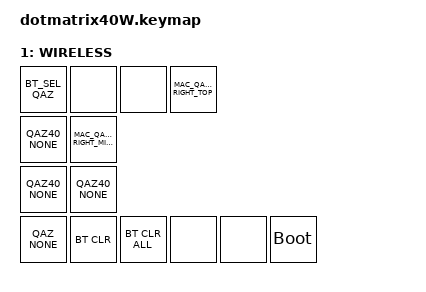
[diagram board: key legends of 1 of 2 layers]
/*
 * Copyright (c) 2021 Nick Winans
 * Copyright 2026 dotting dots
 * Copyright 2026 Tano Karbou (github: karbou12 / X: @karbou_12)
 *
 * SPDX-License-Identifier: MIT
 */

#include <behaviors.dtsi>
#include <dt-bindings/zmk/backlight.h>
#include <dt-bindings/zmk/bt.h>
#include <dt-bindings/zmk/keys.h>

#define ZMK_POINTING_DEFAULT_MOVE_VAL 1500
#define ZMK_POINTING_DEFAULT_SCRL_VAL 50

#include <dt-bindings/zmk/pointing.h>
#include <input/processors.dtsi>
#include <dt-bindings/zmk/input_transform.h>
#include <zephyr/dt-bindings/input/input-event-codes.h>
#include <zmk-input-inertia/input/processor/input_inertia.dtsi>
#include "us_keymap.h"
#include "us_encoder.h"

// ┌────┬────┬────┬────┬────┬────┬────┬────┬────┬────┬────┬────┐
// │  0 │  1 │  2 │  3 │  4 │  5 │  6 │  7 │  8 │  9 │ 10 │ 11 │
// ├────┼────┼────┼────┼────┼────┼────┼────┼────┼────┼────┼────┤
// │ 12 │ 13 │ 14 │ 15 │ 16 │ 17 │ 18 │ 19 │ 20 │ 21 │ 22 │ 23 │
// ├────┼────┼────┼────┼────┼────┼────┼────┼────┼────┼────┼────┤
// │ 24 │ 25 │ 26 │ 27 │ 28 │ 29 │ 30 │ 31 │ 32 │ 33 │ 34 │ 35 │
// ├────┼────┼────┼────┼────┴─┬──┴──┬─┴────┼────┼────┼────┼────┤
// │ 36 │ 37 │ 38 │ 39 │  40  │  E  │  41  │ 42 │ 43 │ 44 │ 45 │
// └────┴────┴────┴────┴──────┴─────┴──────┴────┴────┴────┴────┘

#define LEFT_TOP      0  1  2  3  4  5
#define RIGHT_TOP     6  7  8  9 10 11
#define LEFT_MID      12 13 14 15 16 17
#define RIGHT_MID     18 19 20 21 22 23
#define LEFT_BOTTOM   24 25 26 27 28 29
#define RIGHT_BOTTOM  30 31 32 33 34 35
#define LEFT_THUMBS   36 37 38 39 40
#define RIGHT_THUMBS  41 42 43 44 45
#define LEFT_KEYS LEFT_TOP LEFT_MID LEFT_BOTTOM
#define RIGHT_KEYS RIGHT_TOP RIGHT_MID RIGHT_BOTTOM
#define THUMBS LEFT_THUMBS RIGHT_THUMBS

// for bluetooth
#define WIRELESS  8
#define BT_SEL_QAZ  &bt BT_SEL 0  &bt BT_SEL 1  &bt BT_SEL 2  &bt BT_SEL 3

// original macro

// JIS layout fixes for Japanese OS settings
#define JP_DQUOTE       AT                // "
#define JP_AMPERSAND    CARET             // &
#define JP_QUOTE        AMPERSAND         // '
#define JP_EQUAL        UNDER             // =
#define JP_CARET        EQUAL             // ^
#define JP_YEN          0x89              // ¥
#define JP_PLUS         COLON             // +
#define JP_TILDE        PLUS              // ~
#define JP_PIPE         LS(0x89)          // |
#define JP_AT           LEFT_BRACKET      // @
#define JP_COLON        SINGLE_QUOTE      // :
#define JP_ASTERISK     DOUBLE_QUOTES     // *
#define JP_BACKQUOTE    LEFT_BRACE        // `
#define JP_UNDERSCORE   LS(0x87)          // _
#define JP_LBRACKET     RIGHT_BRACKET     // [
#define JP_RBRACKET     BACKSLASH         // ]
#define JP_LPAREN       ASTERISK          // (
#define JP_RPAREN       LEFT_PARENTHESIS  // )
#define JP_LBRACE       RIGHT_BRACE       // {
#define JP_RBRACE       PIPE              // }
#define JP_KANA         LANGUAGE_1        // Kana
#define JP_EISU         LANGUAGE_2        // Eisu
#define JP_HANZEN       GRAVE             // Han/Zen
#define JP_BSLH         INT1              // Backslash

&msc_input_listener {
    input-processors = <
        &zip_scroll_transform (INPUT_TRANSFORM_X_INVERT | INPUT_TRANSFORM_Y_INVERT)
        &zip_scroll_scaler 1 2
        &zip_inertia
    >;

    snipe {
        layers = <WIRELESS>;
        input-processors = <&zip_xy_to_scroll_mapper &zip_scroll_scaler 1 2>;
        process-next;
    };
};

&mmv_input_listener {
    snipe {
        layers = <WIRELESS>;
        input-processors = <&zip_xy_scaler 1 4>;
    };
};

&zip_inertia {
    // Initiation delay (Wait time after input stops before starting inertia)
    // Recommended: AT LEAST 2x your sensor's polling interval (e.g., 30ms for 15ms sensor).
    trigger-ms = <35>;

    // --- Mouse Movement Settings ---
    move-decay-factor-int = <90>;       // Decay rate (0-100)
    move-report-interval-ms = <35>;     // Report interval (ms)
    move-threshold-start = <15>;        // Start threshold (pix/report)
    move-threshold-stop = <1>;          // Stop threshold (pix/report)

    // --- Scrolling Settings ---
    scroll-decay-factor-int = <90>;    // Scroll decay rate
    scroll-report-interval-ms = <65>;  // Scroll report interval (ms)
    scroll-threshold-start = <2>;      // Start threshold (pix/report)
    scroll-threshold-stop = <0>;       // Stop threshold (pix/report)
};

/ {
    behaviors {
        mtb: mt_balanced {
            compatible = "zmk,behavior-hold-tap";
            #binding-cells = <2>;
            flavor = "balanced";
            tapping-term-ms = <200>;
            quick-tap-ms = <180>;
            bindings = <&kp>, <&kp>;
        };

        hml: home_row_mod_left {
            compatible = "zmk,behavior-hold-tap";
            #binding-cells = <2>;
            flavor = "balanced";
            require-prior-idle-ms = <150>;
            tapping-term-ms = <400>;
            quick-tap-ms = <180>;
            bindings = <&kp>, <&kp>;
            hold-trigger-key-positions = <THUMBS RIGHT_KEYS>;
            hold-trigger-on-release;
        };

        hmr: home_row_mod_right {
            compatible = "zmk,behavior-hold-tap";
            #binding-cells = <2>;
            flavor = "balanced";
            require-prior-idle-ms = <150>;
            tapping-term-ms = <400>;
            quick-tap-ms = <180>;
            bindings = <&kp>, <&kp>;
            hold-trigger-key-positions = <THUMBS LEFT_KEYS>;
            hold-trigger-on-release;
        };

        encoder_backlight: encoder_backlight {
            compatible = "zmk,behavior-sensor-rotate";
            #sensor-binding-cells = <0>;
            bindings = <&bl BL_INC>, <&bl BL_DEC>;
        };

        mo2: mo2 {
            compatible = "zmk,behavior-mod-morph";
            #binding-cells = <0>;
            bindings = <&kp N2>, <&kp JP_DQUOTE>;

            mods = <(MOD_LSFT|MOD_RSFT)>;
        };

        mo6: mo6 {
            compatible = "zmk,behavior-mod-morph";
            #binding-cells = <0>;
            bindings = <&kp N6>, <&kp JP_AMPERSAND>;

            mods = <(MOD_LSFT|MOD_RSFT)>;
        };

        mo7: mo7 {
            compatible = "zmk,behavior-mod-morph";
            #binding-cells = <0>;
            bindings = <&kp N7>, <&kp JP_QUOTE>;

            mods = <(MOD_LSFT|MOD_RSFT)>;
        };

        mo8: mo8 {
            compatible = "zmk,behavior-mod-morph";
            #binding-cells = <0>;
            bindings = <&kp N8>, <&kp JP_LPAREN>;

            mods = <(MOD_LSFT|MOD_RSFT)>;
        };

        mo9: mo9 {
            compatible = "zmk,behavior-mod-morph";
            #binding-cells = <0>;
            bindings = <&kp N9>, <&kp JP_RPAREN>;

            mods = <(MOD_LSFT|MOD_RSFT)>;
        };

        mo0: mo0 {
            compatible = "zmk,behavior-mod-morph";
            #binding-cells = <0>;
            bindings = <&kp N0>, <&none>;

            mods = <(MOD_LSFT|MOD_RSFT)>;
        };

        moA: moA {
            compatible = "zmk,behavior-mod-morph";
            #binding-cells = <0>;
            bindings = <&kp MINUS>, <&kp JP_EQUAL>;

            mods = <(MOD_LSFT|MOD_RSFT)>;
        };

        moB: moB {
            compatible = "zmk,behavior-mod-morph";
            #binding-cells = <0>;
            bindings = <&kp JP_CARET>, <&kp JP_TILDE>;

            mods = <(MOD_LSFT|MOD_RSFT)>;
        };

        moC: moC {
            compatible = "zmk,behavior-mod-morph";
            #binding-cells = <0>;
            bindings = <&kp INT3>, <&kp JP_PIPE>;

            mods = <(MOD_LSFT|MOD_RSFT)>;
        };

        moD: moD {
            compatible = "zmk,behavior-mod-morph";
            #binding-cells = <0>;
            bindings = <&kp JP_AT>, <&kp JP_BACKQUOTE>;

            mods = <(MOD_LSFT|MOD_RSFT)>;
        };

        moE: moE {
            compatible = "zmk,behavior-mod-morph";
            #binding-cells = <0>;
            bindings = <&kp JP_LBRACKET>, <&kp JP_LBRACE>;

            mods = <(MOD_LSFT|MOD_RSFT)>;
        };

        moF: moF {
            compatible = "zmk,behavior-mod-morph";
            #binding-cells = <0>;
            bindings = <&kp SEMI>, <&kp KP_PLUS>;

            mods = <(MOD_LSFT|MOD_RSFT)>;
        };

        moG: moG {
            compatible = "zmk,behavior-mod-morph";
            #binding-cells = <0>;
            bindings = <&kp JP_COLON>, <&kp JP_ASTERISK>;

            mods = <(MOD_LSFT|MOD_RSFT)>;
        };

        moH: moH {
            compatible = "zmk,behavior-mod-morph";
            #binding-cells = <0>;
            bindings = <&kp JP_RBRACKET>, <&kp TILDE2>;

            mods = <(MOD_LSFT|MOD_RSFT)>;
        };

        moI: moI {
            compatible = "zmk,behavior-mod-morph";
            #binding-cells = <0>;
            bindings = <&kp JP_BSLH>, <&kp JP_UNDERSCORE>;

            mods = <(MOD_LSFT|MOD_RSFT)>;
        };
    };

    combos {
        compatible = "zmk,combos";
        combo_capsword {
            timeout-ms = <50>;
            key-positions = <24 35>;
            bindings = <&caps_word>;
        };
    };

    keymap {
        compatible = "zmk,keymap";

#define LAYER(s) MAC_##s##_layer

        LAYER(base) {
            sensor-bindings = <&enc_base_root>;

            bindings = <
                MAC_QAZ40_BASE_LEFT_TOP                 MAC_QAZ40_BASE_RIGHT_TOP
                MAC_QAZ40_BASE_LEFT_MIDDLE              MAC_QAZ40_BASE_RIGHT_MIDDLE
                MAC_QAZ40_BASE_LEFT_BOTTOM              &mkp LCLK  MAC_QAZ_BASE_RIGHT_BOTTOM
                &none  &none  MAC_QAZ_BASE_LEFT_THUMBS  MAC_QAZ_BASE_RIGHT_THUMBS  &none  &none
            >;
        };

        LAYER(raise) {
            sensor-bindings = <&enc_raise_root>;

            bindings = <
                MAC_QAZ40_RAISE_LEFT_TOP                 MAC_QAZ40_RAISE_RIGHT_TOP
                MAC_QAZ40_RAISE_LEFT_MIDDLE              MAC_QAZ40_RAISE_RIGHT_MIDDLE
                MAC_QAZ40_RAISE_LEFT_BOTTOM              MAC_QAZ40_RAISE_RIGHT_BOTTOM
                &none  &none  MAC_QAZ_RAISE_LEFT_THUMBS  MAC_QAZ_RAISE_RIGHT_THUMBS  &none  &none
            >;
        };

        LAYER(lower) {
            sensor-bindings = <&enc_lower_root>;

            bindings = <
                MAC_QAZ40_LOWER_LEFT_TOP                 MAC_QAZ40_LOWER_RIGHT_TOP
                MAC_QAZ40_LOWER_LEFT_MIDDLE              MAC_QAZ40_LOWER_RIGHT_MIDDLE
                MAC_QAZ40_LOWER_LEFT_BOTTOM              MAC_QAZ40_LOWER_RIGHT_BOTTOM
                &none  &none  MAC_QAZ_LOWER_LEFT_THUMBS  MAC_QAZ_LOWER_RIGHT_THUMBS  &none  &none
            >;
        };

        LAYER(adjust) {
            sensor-bindings = <&enc_adjust_root>;

            bindings = <
                MAC_QAZ40_ADJUST_LEFT_TOP                        MAC_QAZ40_ADJUST_RIGHT_TOP
                MAC_QAZ40_ADJUST_LEFT_MIDDLE                     MAC_QAZ40_ADJUST_RIGHT_MIDDLE
                MAC_QAZ40_ADJUST_LEFT_BOTTOM                     MAC_QAZ40_ADJUST_RIGHT_BOTTOM
                &mo WIRELESS  &none  MAC_QAZ_ADJUST_LEFT_THUMBS  MAC_QAZ_ADJUST_RIGHT_THUMBS  &none  &mo WIRELESS
            >;
        };

#undef LAYER
#define LAYER(s) WIN_##s##_layer

        LAYER(base) {
            sensor-bindings = <&enc_base_root>;

            bindings = <
                WIN_QAZ40_BASE_LEFT_TOP                 WIN_QAZ40_BASE_RIGHT_TOP
                WIN_QAZ40_BASE_LEFT_MIDDLE              WIN_QAZ40_BASE_RIGHT_MIDDLE
                WIN_QAZ40_BASE_LEFT_BOTTOM              &mkp LCLK  WIN_QAZ_BASE_RIGHT_BOTTOM
                &none  &none  WIN_QAZ_BASE_LEFT_THUMBS  WIN_QAZ_BASE_RIGHT_THUMBS  &none  &none
            >;
        };

        LAYER(raise) {
            sensor-bindings = <&enc_raise_root>;

            bindings = <
                WIN_QAZ40_RAISE_LEFT_TOP                 WIN_QAZ40_RAISE_RIGHT_TOP
                WIN_QAZ40_RAISE_LEFT_MIDDLE              WIN_QAZ40_RAISE_RIGHT_MIDDLE
                WIN_QAZ40_RAISE_LEFT_BOTTOM              WIN_QAZ40_RAISE_RIGHT_BOTTOM
                &none  &none  WIN_QAZ_RAISE_LEFT_THUMBS  WIN_QAZ_RAISE_RIGHT_THUMBS  &none  &none
            >;
        };

        LAYER(lower) {
            sensor-bindings = <&enc_lower_root>;

            bindings = <
                WIN_QAZ40_LOWER_LEFT_TOP                 WIN_QAZ40_LOWER_RIGHT_TOP
                WIN_QAZ40_LOWER_LEFT_MIDDLE              WIN_QAZ40_LOWER_RIGHT_MIDDLE
                WIN_QAZ40_LOWER_LEFT_BOTTOM              WIN_QAZ40_LOWER_RIGHT_BOTTOM
                &none  &none  WIN_QAZ_LOWER_LEFT_THUMBS  WIN_QAZ_LOWER_RIGHT_THUMBS  &none  &none
            >;
        };

        LAYER(adjust) {
            sensor-bindings = <&enc_adjust_root>;

            bindings = <
                WIN_QAZ40_ADJUST_LEFT_TOP                        WIN_QAZ40_ADJUST_RIGHT_TOP
                WIN_QAZ40_ADJUST_LEFT_MIDDLE                     WIN_QAZ40_ADJUST_RIGHT_MIDDLE
                WIN_QAZ40_ADJUST_LEFT_BOTTOM                     WIN_QAZ40_ADJUST_RIGHT_BOTTOM
                &mo WIRELESS  &none  WIN_QAZ_ADJUST_LEFT_THUMBS  WIN_QAZ_ADJUST_RIGHT_THUMBS  &none  &mo WIRELESS
            >;
        };

        WIRELESS {
            sensor-bindings = <&encoder_backlight>;

            bindings = <
                BT_SEL_QAZ  &none  &none  MAC_QAZ40_ADJUST_RIGHT_TOP
                QAZ40_NONE                MAC_QAZ40_ADJUST_RIGHT_MIDDLE
                QAZ40_NONE                QAZ40_NONE
                QAZ_NONE                  &bt BT_CLR  &bt BT_CLR_ALL  &none  &none  &bootloader
            >;
        };
    };
};

// Override msc behavior to remove acceleration and delay for immediate encoder response

&msc {
    acceleration-exponent = <0>;
    time-to-max-speed-ms = <0>;
    delay-ms = <0>;
};

// Special thanks to the following repository for reference and inspiration:
// https://github.com/kureyakey/zmk-config-zonkey

